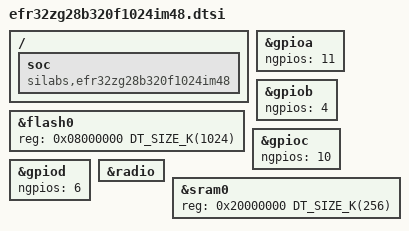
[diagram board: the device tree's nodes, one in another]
/*
 * Copyright (c) 2026 Silicon Laboratories Inc.
 *
 * SPDX-License-Identifier: Apache-2.0
 */

#include <mem.h>
#include <silabs/xg28/efr32zg28.dtsi>

/ {
	soc {
		compatible = "silabs,efr32zg28b320f1024im48", "silabs,efr32zg28", "silabs,xg28",
			     "silabs,efr32", "simple-bus";
	};
};

/delete-node/ &bt_hci_silabs;

&flash0 {
	reg = <0x08000000 DT_SIZE_K(1024)>;
};

&gpioa {
	ngpios = <11>;
};

&gpiob {
	ngpios = <4>;
};

&gpioc {
	ngpios = <10>;
};

&gpiod {
	ngpios = <6>;
};

&radio {
	/delete-property/ pa-2p4ghz;
};

&sram0 {
	reg = <0x20000000 DT_SIZE_K(256)>;
};
